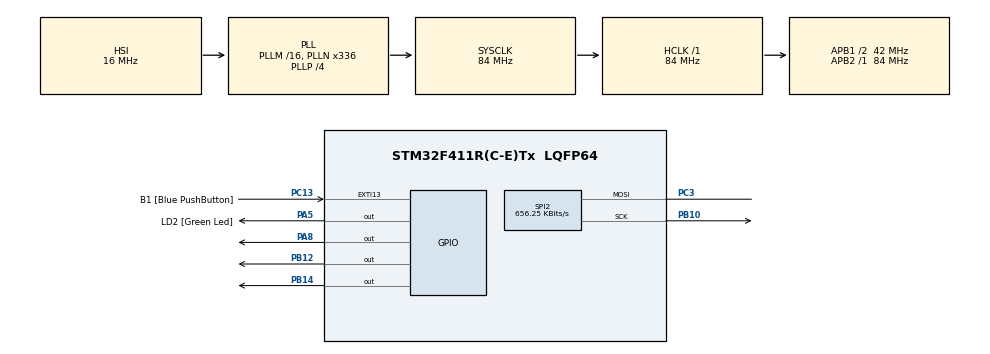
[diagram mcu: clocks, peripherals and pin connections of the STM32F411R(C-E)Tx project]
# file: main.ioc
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Mcu.Family=STM32F4
Mcu.Name=STM32F411R(C-E)Tx
Mcu.Package=LQFP64
NVIC.PriorityGroup=NVIC_PRIORITYGROUP_0
PA13.GPIO_Label=TMS
PA13.Signal=SYS_JTMS-SWDIO
PA14.GPIO_Label=TCK
PA14.Signal=SYS_JTCK-SWCLK
PA2.GPIO_Label=USART_TX
PA2.Signal=USART2_TX
PA3.GPIO_Label=USART_RX
PA3.Signal=USART2_RX
PA5.GPIO_Label=LD2 [Green Led]
PA5.Signal=GPIO_Output
PA8.Signal=GPIO_Output
PB10.Mode=Simplex_Bidirectional_Master
PB10.Signal=SPI2_SCK
PB12.Signal=GPIO_Output
PB14.Signal=GPIO_Output
PB3.GPIO_Label=SWO
PB3.Signal=SYS_JTDO-SWO
PB8.Signal=I2C1_SCL
PB9.Signal=I2C1_SDA
PC13-ANTI_TAMP.GPIO_Label=B1 [Blue PushButton]
PC13-ANTI_TAMP.GPIO_ModeDefaultEXTI=GPIO_MODE_IT_FALLING
PC13-ANTI_TAMP.Signal=GPXTI13
PC14-OSC32_IN.Signal=RCC_OSC32_IN
PC15-OSC32_OUT.Signal=RCC_OSC32_OUT
PC3.Mode=Simplex_Bidirectional_Master
PC3.Signal=SPI2_MOSI
PH0\ -\ OSC_IN.Signal=RCC_OSC_IN
PH1\ -\ OSC_OUT.Signal=RCC_OSC_OUT
ProjectManager.HeapSize=0x200
ProjectManager.StackSize=0x400
ProjectManager.TargetToolchain=Makefile
RCC.48MHZClocksFreq_Value=84000000
RCC.AHBFreq_Value=84000000
RCC.APB1CLKDivider=RCC_HCLK_DIV2
RCC.APB1Freq_Value=42000000
RCC.APB1TimFreq_Value=84000000
RCC.APB2Freq_Value=84000000
RCC.APB2TimFreq_Value=84000000
RCC.CortexFreq_Value=84000000
RCC.FLatency-AdvancedSettings=FLASH_LATENCY_2
RCC.HCLKFreq_Value=84000000
RCC.HSE_VALUE=8000000
RCC.HSI_VALUE=16000000
RCC.LSE_VALUE=32768
RCC.PLLN=336
RCC.PLLP=RCC_PLLP_DIV4
RCC.SYSCLKFreq_VALUE=84000000
RCC.SYSCLKSource=RCC_SYSCLKSOURCE_PLLCLK
RCC.VCOOutputFreq_Value=336000000
SPI2.BaudRatePrescaler=SPI_BAUDRATEPRESCALER_64
SPI2.CalculateBaudRate=656.25 KBits/s
SPI2.Direction=SPI_DIRECTION_1LINE
SPI2.Mode=SPI_MODE_MASTER
SPI2.VirtualType=VM_MASTER
board=NUCLEO-F411RE

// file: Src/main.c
#include "main.h"
#include "stm32f4xx_hal.h"

/* USER CODE BEGIN Includes */
#include "ssd1306_tests.h"
/* USER CODE END Includes */

SPI_HandleTypeDef hspi2;

/* USER CODE BEGIN PV */
/* Private variables ---------------------------------------------------------*/

/* USER CODE END PV */

void SystemClock_Config(void);
static void MX_GPIO_Init(void);
static void MX_SPI2_Init(void);

/* USER CODE BEGIN PFP */
/* Private function prototypes -----------------------------------------------*/

/* USER CODE END PFP */

/* USER CODE BEGIN 0 */
void init() {
	ssd1306_TestAll();
}

void loop() {
	HAL_Delay(100);
}

/* USER CODE END 0 */

int main(void)
{

  /* MCU Configuration----------------------------------------------------------*/

  /* Reset of all peripherals, Initializes the Flash interface and the Systick. */
  HAL_Init();

  /* Configure the system clock */
  SystemClock_Config();

  /* Initialize all configured peripherals */
  MX_GPIO_Init();
  MX_SPI2_Init();

  /* Infinite loop */
  /* USER CODE BEGIN WHILE */
  init();
  while (1)
  {
    loop();
  /* USER CODE END WHILE */

  }

}

/** System Clock Configuration
*/
void SystemClock_Config(void)
{

  RCC_OscInitTypeDef RCC_OscInitStruct;
  RCC_ClkInitTypeDef RCC_ClkInitStruct;

    /**Configure the main internal regulator output voltage
    */
  __HAL_RCC_PWR_CLK_ENABLE();

  __HAL_PWR_VOLTAGESCALING_CONFIG(PWR_REGULATOR_VOLTAGE_SCALE1);

    /**Initializes the CPU, AHB and APB busses clocks
    */
  RCC_OscInitStruct.OscillatorType = RCC_OSCILLATORTYPE_HSI;
  RCC_OscInitStruct.HSIState = RCC_HSI_ON;
  RCC_OscInitStruct.HSICalibrationValue = 16;
  RCC_OscInitStruct.PLL.PLLState = RCC_PLL_ON;
  RCC_OscInitStruct.PLL.PLLSource = RCC_PLLSOURCE_HSI;
  RCC_OscInitStruct.PLL.PLLM = 16;
  RCC_OscInitStruct.PLL.PLLN = 336;
  RCC_OscInitStruct.PLL.PLLP = RCC_PLLP_DIV4;
  RCC_OscInitStruct.PLL.PLLQ = 4;
  if (HAL_RCC_OscConfig(&RCC_OscInitStruct) != HAL_OK)
  {
    _Error_Handler(__FILE__, __LINE__);
  }

    /**Initializes the CPU, AHB and APB busses clocks
    */
  RCC_ClkInitStruct.ClockType = RCC_CLOCKTYPE_HCLK|RCC_CLOCKTYPE_SYSCLK
                              |RCC_CLOCKTYPE_PCLK1|RCC_CLOCKTYPE_PCLK2;
  RCC_ClkInitStruct.SYSCLKSource = RCC_SYSCLKSOURCE_PLLCLK;
  RCC_ClkInitStruct.AHBCLKDivider = RCC_SYSCLK_DIV1;
  RCC_ClkInitStruct.APB1CLKDivider = RCC_HCLK_DIV2;
  RCC_ClkInitStruct.APB2CLKDivider = RCC_HCLK_DIV1;

  if (HAL_RCC_ClockConfig(&RCC_ClkInitStruct, FLASH_LATENCY_2) != HAL_OK)
  {
    _Error_Handler(__FILE__, __LINE__);
  }

    /**Configure the Systick interrupt time
    */
  HAL_SYSTICK_Config(HAL_RCC_GetHCLKFreq()/1000);

    /**Configure the Systick
    */
  HAL_SYSTICK_CLKSourceConfig(SYSTICK_CLKSOURCE_HCLK);

  /* SysTick_IRQn interrupt configuration */
  HAL_NVIC_SetPriority(SysTick_IRQn, 0, 0);
}

/* SPI2 init function */
static void MX_SPI2_Init(void)
{

  /* SPI2 parameter configuration*/
  hspi2.Instance = SPI2;
  hspi2.Init.Mode = SPI_MODE_MASTER;
  hspi2.Init.Direction = SPI_DIRECTION_1LINE;
  hspi2.Init.DataSize = SPI_DATASIZE_8BIT;
  hspi2.Init.CLKPolarity = SPI_POLARITY_LOW;
  hspi2.Init.CLKPhase = SPI_PHASE_1EDGE;
  hspi2.Init.NSS = SPI_NSS_SOFT;
  hspi2.Init.BaudRatePrescaler = SPI_BAUDRATEPRESCALER_64;
  hspi2.Init.FirstBit = SPI_FIRSTBIT_MSB;
  hspi2.Init.TIMode = SPI_TIMODE_DISABLE;
  hspi2.Init.CRCCalculation = SPI_CRCCALCULATION_DISABLE;
  hspi2.Init.CRCPolynomial = 10;
  if (HAL_SPI_Init(&hspi2) != HAL_OK)
  {
    _Error_Handler(__FILE__, __LINE__);
  }

}

/** Configure pins as
        * Analog
        * Input
        * Output
        * EVENT_OUT
        * EXTI
     PA2   ------> USART2_TX
     PA3   ------> USART2_RX
     PB8   ------> I2C1_SCL
     PB9   ------> I2C1_SDA
*/
static void MX_GPIO_Init(void)
{

  GPIO_InitTypeDef GPIO_InitStruct;

  /* GPIO Ports Clock Enable */
  __HAL_RCC_GPIOC_CLK_ENABLE();
  __HAL_RCC_GPIOH_CLK_ENABLE();
  __HAL_RCC_GPIOA_CLK_ENABLE();
  __HAL_RCC_GPIOB_CLK_ENABLE();

  /*Configure GPIO pin Output Level */
  HAL_GPIO_WritePin(GPIOA, LD2_Pin|GPIO_PIN_8, GPIO_PIN_RESET);

  /*Configure GPIO pin Output Level */
  HAL_GPIO_WritePin(GPIOB, GPIO_PIN_12|GPIO_PIN_14, GPIO_PIN_RESET);

  /*Configure GPIO pin : B1_Pin */
  GPIO_InitStruct.Pin = B1_Pin;
  GPIO_InitStruct.Mode = GPIO_MODE_IT_FALLING;
  GPIO_InitStruct.Pull = GPIO_NOPULL;
  HAL_GPIO_Init(B1_GPIO_Port, &GPIO_InitStruct);

  /*Configure GPIO pins : USART_TX_Pin USART_RX_Pin */
  GPIO_InitStruct.Pin = USART_TX_Pin|USART_RX_Pin;
  GPIO_InitStruct.Mode = GPIO_MODE_AF_PP;
  GPIO_InitStruct.Pull = GPIO_NOPULL;
  GPIO_InitStruct.Speed = GPIO_SPEED_FREQ_VERY_HIGH;
  GPIO_InitStruct.Alternate = GPIO_AF7_USART2;
  HAL_GPIO_Init(GPIOA, &GPIO_InitStruct);

  /*Configure GPIO pins : LD2_Pin PA8 */
  GPIO_InitStruct.Pin = LD2_Pin|GPIO_PIN_8;
  GPIO_InitStruct.Mode = GPIO_MODE_OUTPUT_PP;
  GPIO_InitStruct.Pull = GPIO_NOPULL;
  GPIO_InitStruct.Speed = GPIO_SPEED_FREQ_LOW;
  HAL_GPIO_Init(GPIOA, &GPIO_InitStruct);

  /*Configure GPIO pins : PB12 PB14 */
  GPIO_InitStruct.Pin = GPIO_PIN_12|GPIO_PIN_14;
  GPIO_InitStruct.Mode = GPIO_MODE_OUTPUT_PP;
  GPIO_InitStruct.Pull = GPIO_NOPULL;
  GPIO_InitStruct.Speed = GPIO_SPEED_FREQ_LOW;
  HAL_GPIO_Init(GPIOB, &GPIO_InitStruct);

  /*Configure GPIO pins : PB8 PB9 */
  GPIO_InitStruct.Pin = GPIO_PIN_8|GPIO_PIN_9;
  GPIO_InitStruct.Mode = GPIO_MODE_AF_OD;
  GPIO_InitStruct.Pull = GPIO_PULLUP;
  GPIO_InitStruct.Speed = GPIO_SPEED_FREQ_VERY_HIGH;
  GPIO_InitStruct.Alternate = GPIO_AF4_I2C1;
  HAL_GPIO_Init(GPIOB, &GPIO_InitStruct);

}

void _Error_Handler(char * file, int line)
{
  while(1)
  {
  }
}

/************************ (C) COPYRIGHT STMicroelectronics *****END OF FILE****/
